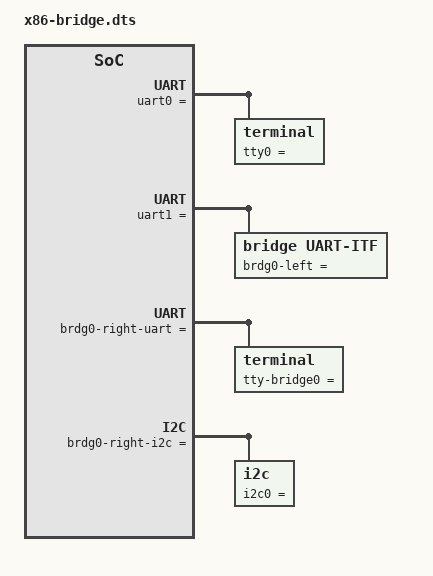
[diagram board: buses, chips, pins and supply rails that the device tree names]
/**
 * Copyright (C) 2022 Jan Nowotsch
 * Author Jan Nowotsch	<jan.nowotsch@gmail.com>
 *
 * Released under the terms of the GNU GPL v2.0
 */



memory = {
	ram = {
		baseaddr = 0x00400000;
		size = 44044288;

		text = {
			baseaddr = 0x00400000;
			size = 20971520;
		};

		kernel-heap = {
			baseaddr = 0x01800000;
			size = 1048576;
		};

		kernel-stack = {
			baseaddr = 0x01900000;
			size = 4096;
		};

		app-heap = {
			baseaddr = 0x01901000;
			size = 1048576;
		};

		app-data = {
			baseaddr = 0x1a01000;
			size = 20971520;
		};
	};
};

devices = {
	uart0 = {
		compatible = "x86,uart";

		/**
		 * uart hardware description
		 * 	has to match the device tree data type
		 *	of the x86 uart driver
		 */
		string = "/dev/stdin";		// path
		int<8> = [
			3,						// rx interrupt
			0						// tx interrupt
		];

		tty0 = {
			compatible = "terminal";

			/**
			 * terminal configuration
			 * 	has to match the configuration data type of
			 * 	the underlying device driver, i.e. uart_cfg_t
			 */
			int<32> = [ 115200 ];	// baudrate
			int<8> = [
				1,					// stop bits (1)
				0,					// parity (TPARITY_NONE)
				3,					// csize (TCS_8)
				0x1,				// iflags (TIFL_CRNL)
				0x2,				// oflags (TOFL_NLCR)
				0x0					// lflags (none)
			];

			klog = {
				compatible = "kernel,log";
			};
		};
	};

	loop0 = {
		compatible = "loop,term";

		/**
		 * loop config
		 *	has to match loop_dt_data_t
		 */
		int<16> = [ 256 ];			// buffer size

		tty-loop0 = {
			compatible = "terminal";

			/**
			 * terminal configuration
			 *	has to match the configuration data type of
			 *	the underlying device driver, i.e. loop_cfg_t
			 */
			int<8> = [
				0x0,				// iflags (none)
				0x0,				// oflags (none)
				0x0					// lflags (none)
			];
		};
	};

	uart1 = {
		compatible = "x86,uart";

		/**
		 * uart hardware description
		 * 	has to match the device tree data type
		 *	of the x86 uart driver
		 */
		string = "/dev/ttyUSB1";	// path
		int<8> = [
			0,						// rx interrupt
			0						// tx interrupt
		];

		brdg0-left = {
			compatible = "bridge,uart-itf";

			/**
			 * bridge hardware description
			 *	has to match bridge_cfg_t
			 */
			/* bridge config */
			int<8> = [
				0,					// id
				2,					// chunksize
				0,					// automatically set by the driver
				0					// automatically set by the driver
			];

			/* terminal config */
			int<32> = [ 115200 ];	// baudrate
			int<8> = [
				1,					// stop bits (1)
				0,					// parity (TPARITY_NONE)
				3,					// csize (TCS_8)
				0x0,				// iflags (none)
				0x0,				// oflags (none)
				0x0					// lflags (none)
			];
		};
	};

	brdg0-right-uart = {
		compatible = "bridge,uart-dev";

		/**
		 * bridge hardware description
		 *	has to match bridge_cfg_t
		 */
		/* bridge config */
		int<8> = [
			0,					// id
			2,					// chunksize
			6,					// rx interrupt
			7					// tx interrupt
		];

		tty-bridge0 = {
			compatible = "terminal";

			/**
			 * terminal configuration
			 * 	has to match the configuration data type of
			 * 	the underlying device driver uart_cfg_t
			 */
			int<32> = [ 115200 ];	// baudrate
			int<8> = [
				1,					// stop bits (1)
				0,					// parity (TPARITY_NONE)
				3,					// csize (TCS_8)
				0x0,				// iflags (none)
				0x0,				// oflags (none)
				0x0					// lflags (none)
			];
		};
	};

	brdg0-right-i2c = {
		compatible = "bridge,i2c-dev";

		/**
		 * bridge hardware description
		 *	has to match bridge_cfg_t
		 */
		/* bridge config */
		int<8> = [
			0,					// id
			2,					// chunksize
			0,					// rx interrupt
			0					// tx interrupt
		];

		/**
		 * i2c configuration
		 *	has to match the configuration data type of
		 *	the underlying device driver
		 */
		int<8> = [ 1 ];			// mode (master)
		int<16> = [ 0 ];		// clock (0kHz)
		int<8> = [
		   0,					// broadcast (enabled)
		   0,					// address
		   0					// interrupt number
		];

		i2c0 = {
			compatible = "i2c";

			/**
			 * i2c devfs dev config
			 *	has to match the configuration of the
			 *	devfs dev device driver
			 */
			 int<8> = [ 0 ];	// slave address
		};
	};
};
